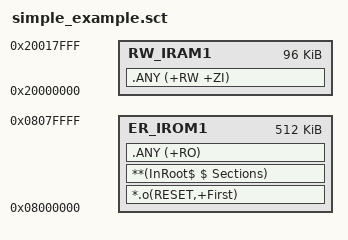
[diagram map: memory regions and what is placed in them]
;simple_example.sct
;*****************************************************
;*************uVision生成的分散加载文件***************
;*****************************************************


LR_IROM1 0x08000000 0x00080000  {    ; load region size_region
  ER_IROM1 0x08000000 0x00080000  {  ; load address = execution address
   *.o(RESET,+First)
   **(InRoot$ $ Sections);本行被注释掉是因为没有使用C库
   .ANY (+RO)
  }
  RW_IRAM1 0x20000000 0x00018000  {  ; RW data
   .ANY (+RW +ZI)
  }
}

